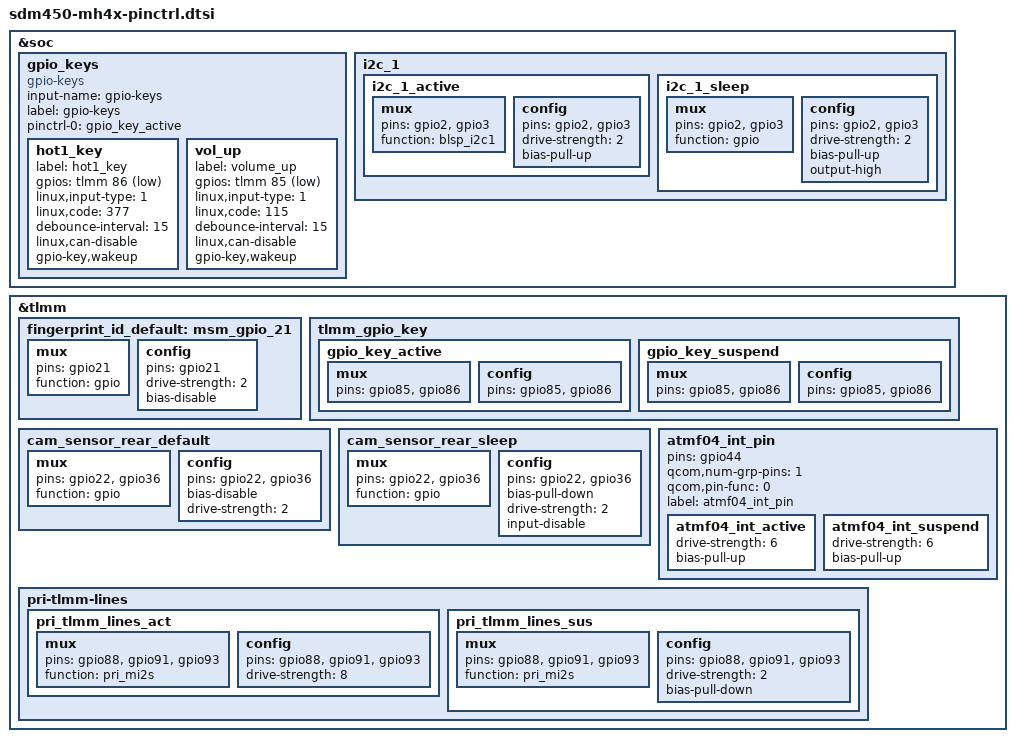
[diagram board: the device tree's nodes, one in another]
/*
 * Copyright (c) 2018, The Linux Foundation. All rights reserved.
 *
 * This program is free software; you can redistribute it and/or modify
 * it under the terms of the GNU General Public License version 2 and
 * only version 2 as published by the Free Software Foundation.
 *
 * This program is distributed in the hope that it will be useful,
 * but WITHOUT ANY WARRANTY; without even the implied warranty of
 * MERCHANTABILITY or FITNESS FOR A PARTICULAR PURPOSE.  See the
 * GNU General Public License for more details.
 */

#include "../sdm450-mh4x_common/sdm450-mh4x_common-pinctrl.dtsi"


&soc {
	gpio_keys {
		compatible = "gpio-keys";
		input-name = "gpio-keys";
		label = "gpio-keys";
		pinctrl-names = "default";
		pinctrl-0 = <&gpio_key_active>;

		hot1_key {
			label = "hot1_key";
			gpios = <&tlmm 86 0x1>;
			linux,input-type = <1>;
			linux,code = <377>;
			debounce-interval = <15>;
			linux,can-disable;
			gpio-key,wakeup;
		};

		vol_up {
			label = "volume_up";
			gpios = <&tlmm 85 0x1>;
			linux,input-type = <1>;
			linux,code = <115>;
			debounce-interval = <15>;
			linux,can-disable;
			gpio-key,wakeup;
		};
	};

	i2c_1 {
			i2c_1_active: i2c_1_active {
				/* active state */
				mux {
					pins = "gpio2", "gpio3";
					function = "blsp_i2c1";
				};

				config {
					pins = "gpio2", "gpio3";
					drive-strength = <2>;
					bias-pull-up;

				};
			};

			i2c_1_sleep: i2c_1_sleep {
				/* suspended state */
				mux {
					pins = "gpio2", "gpio3";
					function = "gpio";
				};

				config {
					pins = "gpio2", "gpio3";
					drive-strength = <2>;
					bias-pull-up;
					output-high;
				};
			};
		};
};

&tlmm {
	fingerprint_id_default: msm_gpio_21 {
		mux {
			pins = "gpio21";
			function = "gpio";
		};

		config {
			pins = "gpio21";
			drive-strength = <2>;
			bias-disable;
		};
	};

	tlmm_gpio_key {
		gpio_key_active: gpio_key_active {
			mux {
				pins = "gpio85", "gpio86";
			};
			config {
				pins = "gpio85", "gpio86";
			};
		};
		gpio_key_suspend: gpio_key_suspend {
			mux {
				pins = "gpio85", "gpio86";
			};
			config {
				pins = "gpio85", "gpio86";
			};
		};
	};

	cam_sensor_rear_default: cam_sensor_rear_default {
		/* RESET, STANDBY */
		mux {
			pins = "gpio22", "gpio36";
			function = "gpio";
		};

		config {
			pins = "gpio22", "gpio36";
			bias-disable; /* No PULL */
			drive-strength = <2>; /* 2 MA */
		};
	};

	cam_sensor_rear_sleep: cam_sensor_rear_sleep {
		/* RESET, STANDBY */
		mux {
			pins = "gpio22", "gpio36";
			function = "gpio";
		};

		config {
			pins = "gpio22", "gpio36";
			bias-pull-down; /* PULL DOWN */
			drive-strength = <2>; /* 2 MA */
			input-disable;
		};
	};

	atmf04_int_pin {
		pins = "gpio44";
		qcom,num-grp-pins = <1>;
		qcom,pin-func = <0>;
		label = "atmf04_int_pin";
		atmf04_int_active: atmf04_int_active {
			drive-strength = <6>;   /* 6 MA */
			bias-pull-up;           /* PULL UP*/
		};
		atmf04_int_suspend: atmf04_int_suspend {
			drive-strength = <6>;   /* 6 MA */
			bias-pull-up;           /* PULL UP */
		};
	};

	pri-tlmm-lines {
		pri_tlmm_lines_act: pri_tlmm_lines_act {
			mux {
				pins = "gpio88", "gpio91", "gpio93";
				function = "pri_mi2s";
			};

			config {
				pins = "gpio88", "gpio91", "gpio93";
				drive-strength = <8>;
			};
		};

		pri_tlmm_lines_sus: pri_tlmm_lines_sus {
			mux {
				pins = "gpio88", "gpio91", "gpio93";
				function = "pri_mi2s";
			};

			config {
				pins = "gpio88", "gpio91", "gpio93";
				drive-strength = <2>;
				bias-pull-down;
			};
		};
	};
};

